AUTOSAR XML (schema 00047)
package /Composition/DiagUT/SwComponentTypes
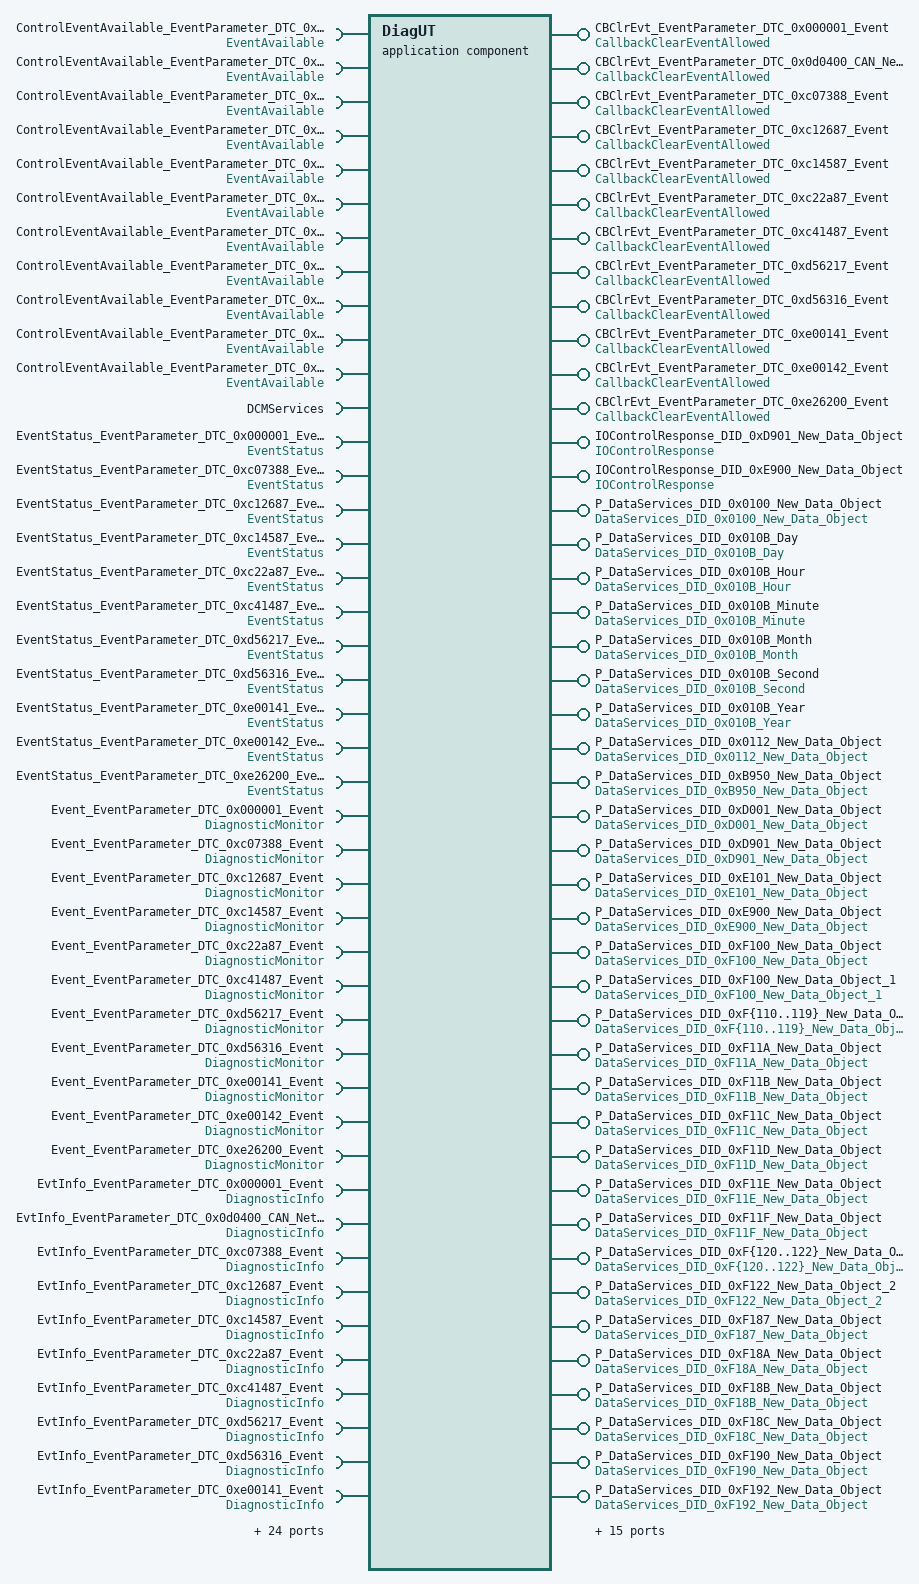
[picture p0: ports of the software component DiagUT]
  application sw component type DiagUT
    12 x provide port, all with provided-interface=CallbackClearEventAllowed:
      CBClrEvt_EventParameter_DTC_0x000001_Event
      CBClrEvt_EventParameter_DTC_0x0d0400_CAN_Network_ETAS_BusOff_Event
      CBClrEvt_EventParameter_DTC_0xc07388_Event
      CBClrEvt_EventParameter_DTC_0xc12687_Event
      CBClrEvt_EventParameter_DTC_0xc14587_Event
      CBClrEvt_EventParameter_DTC_0xc22a87_Event
      CBClrEvt_EventParameter_DTC_0xc41487_Event
      CBClrEvt_EventParameter_DTC_0xd56217_Event
      CBClrEvt_EventParameter_DTC_0xd56316_Event
      CBClrEvt_EventParameter_DTC_0xe00141_Event
      CBClrEvt_EventParameter_DTC_0xe00142_Event
      CBClrEvt_EventParameter_DTC_0xe26200_Event
    49 x require port:
      ControlEventAvailable_EventParameter_DTC_0x000001_Event: required-interface=EventAvailable
      ControlEventAvailable_EventParameter_DTC_0xc07388_Event: required-interface=EventAvailable
      ControlEventAvailable_EventParameter_DTC_0xc12687_Event: required-interface=EventAvailable
      ControlEventAvailable_EventParameter_DTC_0xc14587_Event: required-interface=EventAvailable
      ControlEventAvailable_EventParameter_DTC_0xc22a87_Event: required-interface=EventAvailable
      ControlEventAvailable_EventParameter_DTC_0xc41487_Event: required-interface=EventAvailable
      ControlEventAvailable_EventParameter_DTC_0xd56217_Event: required-interface=EventAvailable
      ControlEventAvailable_EventParameter_DTC_0xd56316_Event: required-interface=EventAvailable
      ControlEventAvailable_EventParameter_DTC_0xe00141_Event: required-interface=EventAvailable
      ControlEventAvailable_EventParameter_DTC_0xe00142_Event: required-interface=EventAvailable
      ControlEventAvailable_EventParameter_DTC_0xe26200_Event: required-interface=EventAvailable
      DCMServices: required-interface=DCMServices
      EventStatus_EventParameter_DTC_0x000001_Event: required-interface=EventStatus
      EventStatus_EventParameter_DTC_0xc07388_Event: required-interface=EventStatus
      EventStatus_EventParameter_DTC_0xc12687_Event: required-interface=EventStatus
      EventStatus_EventParameter_DTC_0xc14587_Event: required-interface=EventStatus
      EventStatus_EventParameter_DTC_0xc22a87_Event: required-interface=EventStatus
      EventStatus_EventParameter_DTC_0xc41487_Event: required-interface=EventStatus
      EventStatus_EventParameter_DTC_0xd56217_Event: required-interface=EventStatus
      EventStatus_EventParameter_DTC_0xd56316_Event: required-interface=EventStatus
      EventStatus_EventParameter_DTC_0xe00141_Event: required-interface=EventStatus
      EventStatus_EventParameter_DTC_0xe00142_Event: required-interface=EventStatus
      EventStatus_EventParameter_DTC_0xe26200_Event: required-interface=EventStatus
      Event_EventParameter_DTC_0x000001_Event: required-interface=DiagnosticMonitor
      Event_EventParameter_DTC_0xc07388_Event: required-interface=DiagnosticMonitor
      Event_EventParameter_DTC_0xc12687_Event: required-interface=DiagnosticMonitor
      Event_EventParameter_DTC_0xc14587_Event: required-interface=DiagnosticMonitor
      Event_EventParameter_DTC_0xc22a87_Event: required-interface=DiagnosticMonitor
      Event_EventParameter_DTC_0xc41487_Event: required-interface=DiagnosticMonitor
      Event_EventParameter_DTC_0xd56217_Event: required-interface=DiagnosticMonitor
      Event_EventParameter_DTC_0xd56316_Event: required-interface=DiagnosticMonitor
      Event_EventParameter_DTC_0xe00141_Event: required-interface=DiagnosticMonitor
      Event_EventParameter_DTC_0xe00142_Event: required-interface=DiagnosticMonitor
      Event_EventParameter_DTC_0xe26200_Event: required-interface=DiagnosticMonitor
      EvtInfo_EventParameter_DTC_0x000001_Event: required-interface=DiagnosticInfo
      EvtInfo_EventParameter_DTC_0x0d0400_CAN_Network_ETAS_BusOff_Event: required-interface=DiagnosticInfo
      EvtInfo_EventParameter_DTC_0xc07388_Event: required-interface=DiagnosticInfo
      EvtInfo_EventParameter_DTC_0xc12687_Event: required-interface=DiagnosticInfo
      EvtInfo_EventParameter_DTC_0xc14587_Event: required-interface=DiagnosticInfo
      EvtInfo_EventParameter_DTC_0xc22a87_Event: required-interface=DiagnosticInfo
      EvtInfo_EventParameter_DTC_0xc41487_Event: required-interface=DiagnosticInfo
      EvtInfo_EventParameter_DTC_0xd56217_Event: required-interface=DiagnosticInfo
      EvtInfo_EventParameter_DTC_0xd56316_Event: required-interface=DiagnosticInfo
      EvtInfo_EventParameter_DTC_0xe00141_Event: required-interface=DiagnosticInfo
      EvtInfo_EventParameter_DTC_0xe00142_Event: required-interface=DiagnosticInfo
      EvtInfo_EventParameter_DTC_0xe26200_Event: required-interface=DiagnosticInfo
      GeneralEvtInfo: required-interface=GeneralDiagnosticInfo
      IOControlRequest_DID_0xD901_New_Data_Object: required-interface=IOControlRequest_DID_0xD901_New_Data_Object
      IOControlRequest_DID_0xE900_New_Data_Object: required-interface=IOControlRequest_DID_0xE900_New_Data_Object
    provide port IOControlResponse_DID_0xD901_New_Data_Object: provided-interface=IOControlResponse
    provide port IOControlResponse_DID_0xE900_New_Data_Object: provided-interface=IOControlResponse
    require port OpCycle_DemOpCycle_DEM_POWER: required-interface=OperationCycle
    53 x provide port:
      P_DataServices_DID_0x0100_New_Data_Object: provided-interface=DataServices_DID_0x0100_New_Data_Object
      P_DataServices_DID_0x010B_Day: provided-interface=DataServices_DID_0x010B_Day
      P_DataServices_DID_0x010B_Hour: provided-interface=DataServices_DID_0x010B_Hour
      P_DataServices_DID_0x010B_Minute: provided-interface=DataServices_DID_0x010B_Minute
      P_DataServices_DID_0x010B_Month: provided-interface=DataServices_DID_0x010B_Month
      P_DataServices_DID_0x010B_Second: provided-interface=DataServices_DID_0x010B_Second
      P_DataServices_DID_0x010B_Year: provided-interface=DataServices_DID_0x010B_Year
      P_DataServices_DID_0x0112_New_Data_Object: provided-interface=DataServices_DID_0x0112_New_Data_Object
      P_DataServices_DID_0xB950_New_Data_Object: provided-interface=DataServices_DID_0xB950_New_Data_Object
      P_DataServices_DID_0xD001_New_Data_Object: provided-interface=DataServices_DID_0xD001_New_Data_Object
      P_DataServices_DID_0xD901_New_Data_Object: provided-interface=DataServices_DID_0xD901_New_Data_Object
      P_DataServices_DID_0xE101_New_Data_Object: provided-interface=DataServices_DID_0xE101_New_Data_Object
      P_DataServices_DID_0xE900_New_Data_Object: provided-interface=DataServices_DID_0xE900_New_Data_Object
      P_DataServices_DID_0xF100_New_Data_Object: provided-interface=DataServices_DID_0xF100_New_Data_Object
      P_DataServices_DID_0xF100_New_Data_Object_1: provided-interface=DataServices_DID_0xF100_New_Data_Object_1
      P_DataServices_DID_0xF{110..119}_New_Data_Object: provided-interface=DataServices_DID_0xF{110..119}_New_Data_Object
      P_DataServices_DID_0xF11A_New_Data_Object: provided-interface=DataServices_DID_0xF11A_New_Data_Object
      P_DataServices_DID_0xF11B_New_Data_Object: provided-interface=DataServices_DID_0xF11B_New_Data_Object
      P_DataServices_DID_0xF11C_New_Data_Object: provided-interface=DataServices_DID_0xF11C_New_Data_Object
      P_DataServices_DID_0xF11D_New_Data_Object: provided-interface=DataServices_DID_0xF11D_New_Data_Object
      P_DataServices_DID_0xF11E_New_Data_Object: provided-interface=DataServices_DID_0xF11E_New_Data_Object
      P_DataServices_DID_0xF11F_New_Data_Object: provided-interface=DataServices_DID_0xF11F_New_Data_Object
      P_DataServices_DID_0xF{120..122}_New_Data_Object: provided-interface=DataServices_DID_0xF{120..122}_New_Data_Object
      P_DataServices_DID_0xF122_New_Data_Object_2: provided-interface=DataServices_DID_0xF122_New_Data_Object_2
      P_DataServices_DID_0xF187_New_Data_Object: provided-interface=DataServices_DID_0xF187_New_Data_Object
      P_DataServices_DID_0xF18A_New_Data_Object: provided-interface=DataServices_DID_0xF18A_New_Data_Object
      P_DataServices_DID_0xF18B_New_Data_Object: provided-interface=DataServices_DID_0xF18B_New_Data_Object
      P_DataServices_DID_0xF18C_New_Data_Object: provided-interface=DataServices_DID_0xF18C_New_Data_Object
      P_DataServices_DID_0xF190_New_Data_Object: provided-interface=DataServices_DID_0xF190_New_Data_Object
      P_DataServices_DID_0xF192_New_Data_Object: provided-interface=DataServices_DID_0xF192_New_Data_Object
      P_DataServices_DID_0xF192_New_Data_Object_3: provided-interface=DataServices_DID_0xF192_New_Data_Object_3
      P_DataServices_DID_0xF194_New_Data_Object: provided-interface=DataServices_DID_0xF194_New_Data_Object
      P_DataServices_DID_0xF194_New_Data_Object_4: provided-interface=DataServices_DID_0xF194_New_Data_Object_4
      P_DataServices_DID_0xF198_New_Data_Object: provided-interface=DataServices_DID_0xF198_New_Data_Object
      P_DataServices_DID_0xF198_New_Data_Object_5: provided-interface=DataServices_DID_0xF198_New_Data_Object_5
      P_DataServices_DID_0xF1A{0..2}_New_Data_Object: provided-interface=DataServices_DID_0xF1A{0..2}_New_Data_Object
      P_DataServices_DID_0xF1A5_New_Data_Object: provided-interface=DataServices_DID_0xF1A5_New_Data_Object
      P_DataServices_DID_0xF1A8_New_Data_Object: provided-interface=DataServices_DID_0xF1A8_New_Data_Object
      P_DataServices_DID_0xF1A9_New_Data_Object: provided-interface=DataServices_DID_0xF1A9_New_Data_Object
      P_DataServices_DID_0xF1AA_New_Data_Object: provided-interface=DataServices_DID_0xF1AA_New_Data_Object
    17 x require port:
      RR_DcmCommunicationControl_ComMChannel_Can_Network_ETAS_Channel: required-interface=DcmCommunicationControl_Can_Network_ETAS_Channel_Can_Network_ETAS
      RR_DcmControlDTCSetting: required-interface=DcmControlDTCSetting
      RR_DcmDiagnosticSessionControl: required-interface=DcmDiagnosticSessionControl
      RR_DcmEcuReset: required-interface=DcmEcuReset
      R_DataServices_DID_0x0100_New_Data_Object: required-interface=DataServices_DID_0x0100_New_Data_Object
      R_DataServices_DID_0xF110_New_Data_Object: required-interface=DataServices_DID_0xF110_New_Data_Object
      R_DataServices_DID_0xF115_New_Data_Object: required-interface=DataServices_DID_0xF115_New_Data_Object
      R_DataServices_DID_0xF121_New_Data_Object: required-interface=DataServices_DID_0xF121_New_Data_Object
      R_DataServices_DID_0xF187_New_Data_Object: required-interface=DataServices_DID_0xF187_New_Data_Object
      R_DataServices_DID_0xF18B_New_Data_Object: required-interface=DataServices_DID_0xF18B_New_Data_Object
      R_DataServices_DID_0xF18C_New_Data_Object: required-interface=DataServices_DID_0xF18C_New_Data_Object
      R_DataServices_DID_0xF190_New_Data_Object: required-interface=DataServices_DID_0xF190_New_Data_Object
      R_DataServices_DID_0xF198_New_Data_Object: required-interface=DataServices_DID_0xF198_New_Data_Object
      R_DataServices_DID_0xF198_New_Data_Object_5: required-interface=DataServices_DID_0xF198_New_Data_Object_5
      R_DataServices_DID_0xF1A8_New_Data_Object: required-interface=DataServices_DID_0xF1A8_New_Data_Object
      R_DataServices_DID_0xF1A9_New_Data_Object: required-interface=DataServices_DID_0xF1A9_New_Data_Object
      R_DataServices_DID_0xF1AA_New_Data_Object: required-interface=DataServices_DID_0xF1AA_New_Data_Object
    5 x provide port:
      RoutineServices_DcmDspRoutine_Routine_Control_203: provided-interface=RoutineServices_Routine_Control_203
      RoutineServices_DcmDspRoutine_Routine_Control_ABFF: provided-interface=RoutineServices_Routine_Control_ABFF
      RoutineServices_DcmDspRoutine_X_Routine_Control_ABFE: provided-interface=RoutineServices_X_Routine_Control_ABFE
      SecurityAccess_UnlockedL1: provided-interface=SecurityAccess_UnlockedL1
      SecurityAccess_Unlocked_L3: provided-interface=SecurityAccess_Unlocked_L3
    require port StorageCond_DemStorageCondition_0: required-interface=StorageCondition
    behavior IB_DiagUT: data-type-mapping=[DTS_DcmDiagnosticSessionControl, DTS_DcmEcuReset, DTS_DcmControlDTCSetting, DTS_DcmDspDid_FOR_DEM_SR_FF_267_Year, DTS_DcmDspDid_FOR_DEM_SR_FF_267_Month, DTS_DcmDspDid_FOR_DEM_SR_FF_267_Day, DTS_DcmDspDid_FOR_DEM_SR_FF_267_Hour, DTS_DcmDspDid_FOR_DEM_SR_FF_267_Minute, DTS_DcmDspDid_FOR_DEM_SR_FF_267_Second, DTS_DcmDspDid_FOR_DEM_SR_FF_274_New_Data_Object, DTS_DcmDspDid_FOR_DEM_SR_FF_53249_New_Data_Object, DTS_DcmDspDid_FOR_DEM_SR_FF_55553_New_Data_Object, DTS_DcmDspDid_DID_0x0100_New_Data_Object, DTS_DcmDspDid_DID_0x010B_Year, DTS_DcmDspDid_DID_0x010B_Month, DTS_DcmDspDid_DID_0x010B_Day, DTS_DcmDspDid_DID_0x010B_Hour, DTS_DcmDspDid_DID_0x010B_Minute, DTS_DcmDspDid_DID_0x010B_Second, DTS_DcmDspDid_DID_0x0112_New_Data_Object, DTS_DcmDspDid_DID_0xB950_New_Data_Object, DTS_DcmDspDid_DID_0xD001_New_Data_Object, DTS_DcmDspDid_DID_0xD901_New_Data_Object, DTS_DcmDspDid_DID_0xE101_New_Data_Object, DTS_DcmDspDid_DID_0xE900_New_Data_Object, DTS_DcmDspDid_DID_0xF100_New_Data_Object, DTS_DcmDspDid_DID_0xF100_New_Data_Object_1, DTS_DcmDspDid_DID_0xF110_New_Data_Object, DTS_DcmDspDid_DID_0xF111_New_Data_Object, DTS_DcmDspDid_DID_0xF112_New_Data_Object, DTS_DcmDspDid_DID_0xF113_New_Data_Object, DTS_DcmDspDid_DID_0xF114_New_Data_Object, DTS_DcmDspDid_DID_0xF115_New_Data_Object, DTS_DcmDspDid_DID_0xF116_New_Data_Object, DTS_DcmDspDid_DID_0xF117_New_Data_Object, DTS_DcmDspDid_DID_0xF118_New_Data_Object, DTS_DcmDspDid_DID_0xF119_New_Data_Object, DTS_DcmDspDid_DID_0xF11A_New_Data_Object, DTS_DcmDspDid_DID_0xF11B_New_Data_Object, DTS_DcmDspDid_DID_0xF11C_New_Data_Object, DTS_DcmDspDid_DID_0xF11D_New_Data_Object, DTS_DcmDspDid_DID_0xF11E_New_Data_Object, DTS_DcmDspDid_DID_0xF11F_New_Data_Object, DTS_DcmDspDid_DID_0xF120_New_Data_Object, DTS_DcmDspDid_DID_0xF121_New_Data_Object, DTS_DcmDspDid_DID_0xF122_New_Data_Object, DTS_DcmDspDid_DID_0xF122_New_Data_Object_2, DTS_DcmDspDid_DID_0xF187_New_Data_Object, DTS_DcmDspDid_DID_0xF18A_New_Data_Object, DTS_DcmDspDid_DID_0xF18B_New_Data_Object, DTS_DcmDspDid_DID_0xF18C_New_Data_Object, DTS_DcmDspDid_DID_0xF190_New_Data_Object, DTS_DcmDspDid_DID_0xF192_New_Data_Object, DTS_DcmDspDid_DID_0xF192_New_Data_Object_3, DTS_DcmDspDid_DID_0xF194_New_Data_Object, DTS_DcmDspDid_DID_0xF194_New_Data_Object_4, DTS_DcmDspDid_DID_0xF198_New_Data_Object, DTS_DcmDspDid_DID_0xF198_New_Data_Object_5, DTS_DcmDspDid_DID_0xF1A0_New_Data_Object, DTS_DcmDspDid_DID_0xF1A1_New_Data_Object, DTS_DcmDspDid_DID_0xF1A2_New_Data_Object, DTS_DcmDspDid_DID_0xF1A5_New_Data_Object, DTS_DcmDspDid_DID_0xF1A8_New_Data_Object, DTS_DcmDspDid_DID_0xF1A9_New_Data_Object, DTS_DcmDspDid_DID_0xF1AA_New_Data_Object, DTS_DcmCommunicationControl_Can_Network_ETAS_Channel_Can_Network_ETAS, DTS_DcmDspRoutine_Routine_Control_203_StartOut_DcmDspStartRoutineOutSignal_0, DTS_DcmDspRoutine_Routine_Control_ABFF_RequestResultsOut_DcmDspRequestRoutineResultsOutSignal_0]
      16 x operation invoked event:
        OIE_CBClrEvt_EventParameter_DTC_0x0d0400_CAN_Network_ETAS_BusOff_Event_ClearEventAllowed_Ev: start-on-event=CBClrEvt_EventParameter_DTC_0x0d0400_CAN_Network_ETAS_BusOff_Event_ClearEventAllowed, operation=CBClrEvt_EventParameter_DTC_0x0d0400_CAN_Network_ETAS_BusOff_Event.ClearEventAllowed
        OIE_CBClrEvt_EventParameter_DTC_0xc07388_Event_ClearEventAllowed_Ev: start-on-event=CBClrEvt_EventParameter_DTC_0xc07388_Event_ClearEventAllowed, operation=CBClrEvt_EventParameter_DTC_0xc07388_Event.ClearEventAllowed
        OIE_CBClrEvt_EventParameter_DTC_0xc12687_Event_ClearEventAllowed_Ev: start-on-event=CBClrEvt_EventParameter_DTC_0xc12687_Event_ClearEventAllowed, operation=CBClrEvt_EventParameter_DTC_0xc12687_Event.ClearEventAllowed
        OIE_CBClrEvt_EventParameter_DTC_0xc14587_Event_ClearEventAllowed_Ev: start-on-event=CBClrEvt_EventParameter_DTC_0xc14587_Event_ClearEventAllowed, operation=CBClrEvt_EventParameter_DTC_0xc14587_Event.ClearEventAllowed
        OIE_CBClrEvt_EventParameter_DTC_0xc22a87_Event_ClearEventAllowed_Ev: start-on-event=CBClrEvt_EventParameter_DTC_0xc22a87_Event_ClearEventAllowed, operation=CBClrEvt_EventParameter_DTC_0xc22a87_Event.ClearEventAllowed
        OIE_CBClrEvt_EventParameter_DTC_0xc41487_Event_ClearEventAllowed_Ev: start-on-event=CBClrEvt_EventParameter_DTC_0xc41487_Event_ClearEventAllowed, operation=CBClrEvt_EventParameter_DTC_0xc41487_Event.ClearEventAllowed
        OIE_CBClrEvt_EventParameter_DTC_0xd56217_Event_ClearEventAllowed_Ev: start-on-event=CBClrEvt_EventParameter_DTC_0xd56217_Event_ClearEventAllowed, operation=CBClrEvt_EventParameter_DTC_0xd56217_Event.ClearEventAllowed
        OIE_CBClrEvt_EventParameter_DTC_0xd56316_Event_ClearEventAllowed_Ev: start-on-event=CBClrEvt_EventParameter_DTC_0xd56316_Event_ClearEventAllowed, operation=CBClrEvt_EventParameter_DTC_0xd56316_Event.ClearEventAllowed
        OIE_CBClrEvt_EventParameter_DTC_0xe00141_Event_ClearEventAllowed_Ev: start-on-event=CBClrEvt_EventParameter_DTC_0xe00141_Event_ClearEventAllowed, operation=CBClrEvt_EventParameter_DTC_0xe00141_Event.ClearEventAllowed
        OIE_CBClrEvt_EventParameter_DTC_0xe00142_Event_ClearEventAllowed_Ev: start-on-event=CBClrEvt_EventParameter_DTC_0xe00142_Event_ClearEventAllowed, operation=CBClrEvt_EventParameter_DTC_0xe00142_Event.ClearEventAllowed
        OIE_CBClrEvt_EventParameter_DTC_0xe26200_Event_ClearEventAllowed_Ev: start-on-event=CBClrEvt_EventParameter_DTC_0xe26200_Event_ClearEventAllowed, operation=CBClrEvt_EventParameter_DTC_0xe26200_Event.ClearEventAllowed
        OIE_ClearEventAllowed_Ev: start-on-event=ClearEventAllowed, operation=CBClrEvt_EventParameter_DTC_0x000001_Event.ClearEventAllowed
        OIE_SecurityAccess_Unlocked_L1_CompareKey_Ev: start-on-event=SecurityAccess_Unlocked_L1_CompareKey, operation=SecurityAccess_UnlockedL1.CompareKey
        OIE_SecurityAccess_Unlocked_L1_GetSeed_Ev: start-on-event=SecurityAccess_Unlocked_L1_GetSeed, operation=SecurityAccess_UnlockedL1.GetSeed
        OIE_SecurityAccess_Unlocked_L3_CompareKey_Ev: start-on-event=SecurityAccess_Unlocked_L3_CompareKey, operation=SecurityAccess_Unlocked_L3.CompareKey
        OIE_SecurityAccess_Unlocked_L3_GetSeed_Ev: start-on-event=SecurityAccess_Unlocked_L3_GetSeed, operation=SecurityAccess_Unlocked_L3.GetSeed
      41 x timing event, all with period=0.01:
        TE_ClearPrestoredFreezeFrame_Adapt_Appl: start-on-event=ClearPrestoredFreezeFrame_Adapt_Appl
        TE_Dcm_GetActiveProtocol_Adapt_Appl: start-on-event=Dcm_GetActiveProtocol_Adapt_Appl
        TE_Dcm_GetSecurityLevel_Adapt_Appl: start-on-event=Dcm_GetSecurityLevel_Adapt_Appl
        TE_Dcm_GetSesCtrlType_Adapt_Appl: start-on-event=Dcm_GetSesCtrlType_Adapt_Appl
        TE_Dcm_ResetToDefaultSession_Adapt_Appl: start-on-event=Dcm_ResetToDefaultSession_Adapt_Appl
        TE_Dcm_SetActiveDiagnostic_Adapt_Appl: start-on-event=Dcm_SetActiveDiagnostic_Adapt_Appl
        TE_Dem_GetDTCOfEvent_GeneralEvtInfo_Adapt_Appl: start-on-event=Dem_GetDTCOfEvent_GeneralEvtInfo_Adapt_Appl
        TE_Dem_GetEventExtendedDataRecordEx_GeneralEvtInfo_Adapt_Appl: start-on-event=Dem_GetEventExtendedDataRecordEx_GeneralEvtInfo_Adapt_Appl
        TE_Dem_GetEventExtendedDataRecord_GeneralEvtInfo_Adapt_Appl: start-on-event=Dem_GetEventExtendedDataRecord_GeneralEvtInfo_Adapt_Appl
        TE_Dem_GetEventFailed_GeneralEvtInfo_Adapt_Appl: start-on-event=Dem_GetEventFailed_GeneralEvtInfo_Adapt_Appl
        TE_Dem_GetEventFreezeFrameDataEx_GeneralEvtInfo_Adapt_Appl: start-on-event=Dem_GetEventFreezeFrameDataEx_GeneralEvtInfo_Adapt_Appl
        TE_Dem_GetEventFreezeFrameData_GeneralEvtInfo_Adapt_Appl: start-on-event=Dem_GetEventFreezeFrameData_GeneralEvtInfo_Adapt_Appl
        TE_Dem_GetEventIdCausingLastDetError_Adapt_Appl: start-on-event=Dem_GetEventIdCausingLastDetError_Adapt_Appl
        TE_Dem_GetEventStatus_GeneralEvtInfo_Adapt_Appl: start-on-event=Dem_GetEventStatus_GeneralEvtInfo_Adapt_Appl
        TE_Dem_GetEventTested_GeneralEvtInfo_Adapt_Appl: start-on-event=Dem_GetEventTested_GeneralEvtInfo_Adapt_Appl
        TE_Dem_GetFaultDetectionCounter_GeneralEvtInfo_Adapt_Appl: start-on-event=Dem_GetFaultDetectionCounter_GeneralEvtInfo_Adapt_Appl
        TE_GetCycleQualified_Adapt_Appl: start-on-event=GetCycleQualified_Adapt_Appl
        TE_GetDTCOfEvent_Adapt_Appl: start-on-event=GetDTCOfEvent_Adapt_Appl
        TE_GetDebouncingOfEvent_Adapt_Appl: start-on-event=GetDebouncingOfEvent_Adapt_Appl
        TE_GetDebouncingOfEvent_GeneralEvtInfo_Adapt_Appl: start-on-event=GetDebouncingOfEvent_GeneralEvtInfo_Adapt_Appl
        TE_GetEventExtendedDataRecordEx_Adapt_Appl: start-on-event=GetEventExtendedDataRecordEx_Adapt_Appl
        TE_GetEventExtendedDataRecord_Adapt_Appl: start-on-event=GetEventExtendedDataRecord_Adapt_Appl
        TE_GetEventFailed_Adapt_Appl: start-on-event=GetEventFailed_Adapt_Appl
        TE_GetEventFreezeFrameDataEx_Adapt_Appl: start-on-event=GetEventFreezeFrameDataEx_Adapt_Appl
        TE_GetEventFreezeFrameData_Adapt_Appl: start-on-event=GetEventFreezeFrameData_Adapt_Appl
        TE_GetEventStatus_Adapt_Appl: start-on-event=GetEventStatus_Adapt_Appl
        TE_GetEventTested_Adapt_Appl: start-on-event=GetEventTested_Adapt_Appl
        TE_GetFaultDetectionCounter_Adapt_Appl: start-on-event=GetFaultDetectionCounter_Adapt_Appl
        TE_GetOperationCycleState_Adapt_Appl: start-on-event=GetOperationCycleState_Adapt_Appl
        TE_GetStorageCondition_Adapt_Appl: start-on-event=GetStorageCondition_Adapt_Appl
        TE_PrestoreFreezeFrame_Adapt_Appl: start-on-event=PrestoreFreezeFrame_Adapt_Appl
        TE_ResetEventDebounceStatus_Adapt_Appl: start-on-event=ResetEventDebounceStatus_Adapt_Appl
        TE_ResetEventStatus_Adapt_Appl: start-on-event=ResetEventStatus_Adapt_Appl
        TE_SetCycleQualified_Adapt_Appl: start-on-event=SetCycleQualified_Adapt_Appl
        TE_SetEventAvailable_Adapt_Appl: start-on-event=SetEventAvailable_Adapt_Appl
        TE_SetEventStatusWithEnvdata_Adapt_Appl: start-on-event=SetEventStatusWithEnvdata_Adapt_Appl
        TE_SetEventStatus_Adapt_Appl: start-on-event=SetEventStatus_Adapt_Appl
        TE_SetOperationCycleState_Adapt_Appl: start-on-event=SetOperationCycleState_Adapt_Appl
        TE_SetStorageCondition_Adapt_Appl: start-on-event=SetStorageCondition_Adapt_Appl
        TE_SetWIRStatus_Adapt_Appl: start-on-event=SetWIRStatus_Adapt_Appl
        TE_Dcm_MainFunction_Adapt_Appl: start-on-event=Dcm_MainFunction_Adapt_Appl
      4 x operation invoked event:
        OIE_RoutineServices_DcmDspRoutine_Routine_Control_203_Start_Ev: start-on-event=RoutineServices_DcmDspRoutine_Routine_Control_203_Start, operation=RoutineServices_DcmDspRoutine_Routine_Control_203.Start
        OIE_RoutineServices_DcmDspRoutine_Routine_Control_ABFF_Start_Ev: start-on-event=RoutineServices_DcmDspRoutine_Routine_Control_ABFF_Start, operation=RoutineServices_DcmDspRoutine_Routine_Control_ABFF.Start
        OIE_RoutineServices_DcmDspRoutine_Routine_Control_ABFF_RequestResults_Ev: start-on-event=RoutineServices_DcmDspRoutine_Routine_Control_ABFF_RequestResults, operation=RoutineServices_DcmDspRoutine_Routine_Control_ABFF.RequestResults
        OIE_RoutineServices_DcmDspRoutine_X_Routine_Control_ABFE_Start_Ev: start-on-event=RoutineServices_DcmDspRoutine_X_Routine_Control_ABFE_Start, operation=RoutineServices_DcmDspRoutine_X_Routine_Control_ABFE.Start
      61 x runnable:
        CBClrEvt_EventParameter_DTC_0x0d0400_CAN_Network_ETAS_BusOff_Event_ClearEventAllowed: can-be-invoked-concurrently=true
        CBClrEvt_EventParameter_DTC_0xc07388_Event_ClearEventAllowed: can-be-invoked-concurrently=true
        CBClrEvt_EventParameter_DTC_0xc12687_Event_ClearEventAllowed: can-be-invoked-concurrently=true
        CBClrEvt_EventParameter_DTC_0xc14587_Event_ClearEventAllowed: can-be-invoked-concurrently=true
        CBClrEvt_EventParameter_DTC_0xc22a87_Event_ClearEventAllowed: can-be-invoked-concurrently=true
        CBClrEvt_EventParameter_DTC_0xc41487_Event_ClearEventAllowed: can-be-invoked-concurrently=true
        CBClrEvt_EventParameter_DTC_0xd56217_Event_ClearEventAllowed: can-be-invoked-concurrently=true
        CBClrEvt_EventParameter_DTC_0xd56316_Event_ClearEventAllowed: can-be-invoked-concurrently=true
        CBClrEvt_EventParameter_DTC_0xe00141_Event_ClearEventAllowed: can-be-invoked-concurrently=true
        CBClrEvt_EventParameter_DTC_0xe00142_Event_ClearEventAllowed: can-be-invoked-concurrently=true
        CBClrEvt_EventParameter_DTC_0xe26200_Event_ClearEventAllowed: can-be-invoked-concurrently=true
        ClearEventAllowed: can-be-invoked-concurrently=true
        ClearPrestoredFreezeFrame_Adapt_Appl
          11 x sync call:
            SynchronousServerCallPoint_0: operation=Event_EventParameter_DTC_0x000001_Event.ClearPrestoredFreezeFrame
            SynchronousServerCallPoint_1: operation=Event_EventParameter_DTC_0xc07388_Event.ClearPrestoredFreezeFrame
            SynchronousServerCallPoint_10: operation=Event_EventParameter_DTC_0xe26200_Event.ClearPrestoredFreezeFrame
            SynchronousServerCallPoint_2: operation=Event_EventParameter_DTC_0xc12687_Event.ClearPrestoredFreezeFrame
            SynchronousServerCallPoint_3: operation=Event_EventParameter_DTC_0xc14587_Event.ClearPrestoredFreezeFrame
            SynchronousServerCallPoint_4: operation=Event_EventParameter_DTC_0xc22a87_Event.ClearPrestoredFreezeFrame
            SynchronousServerCallPoint_5: operation=Event_EventParameter_DTC_0xc41487_Event.ClearPrestoredFreezeFrame
            SynchronousServerCallPoint_6: operation=Event_EventParameter_DTC_0xd56217_Event.ClearPrestoredFreezeFrame
            SynchronousServerCallPoint_7: operation=Event_EventParameter_DTC_0xd56316_Event.ClearPrestoredFreezeFrame
            SynchronousServerCallPoint_8: operation=Event_EventParameter_DTC_0xe00141_Event.ClearPrestoredFreezeFrame
            SynchronousServerCallPoint_9: operation=Event_EventParameter_DTC_0xe00142_Event.ClearPrestoredFreezeFrame
        Dcm_GetActiveProtocol_Adapt_Appl
          sync call SynchronousServerCallPoint_0: operation=DCMServices.GetActiveProtocol
        Dcm_GetSecurityLevel_Adapt_Appl
          sync call SynchronousServerCallPoint_0: operation=DCMServices.GetSecurityLevel
        Dcm_GetSesCtrlType_Adapt_Appl
          sync call SynchronousServerCallPoint_0: operation=DCMServices.GetSesCtrlType
        Dcm_MainFunction_Adapt_Appl
          data-receive-point-by-arguments:
            15 x access:
              DRPA_IOControlRequest_DID_0xD901_New_Data_Object_IOControlRequest_DID_0xD901_New_Data_Object: accessed-variable=IOControlRequest_DID_0xD901_New_Data_Object.IOControlRequest_DID_0xD901_New_Data_Object
              DRPA_IOControlRequest_DID_0xE900_New_Data_Object_IOControlRequest_DID_0xE900_New_Data_Object: accessed-variable=IOControlRequest_DID_0xE900_New_Data_Object.IOControlRequest_DID_0xE900_New_Data_Object
              DRPA_R_DataServices_DID_0x0100_New_Data_Object_Data: accessed-variable=R_DataServices_DID_0x0100_New_Data_Object.Data
              DRPA_R_DataServices_DID_0xF110_New_Data_Object_Data: accessed-variable=R_DataServices_DID_0xF110_New_Data_Object.Data
              DRPA_R_DataServices_DID_0xF115_New_Data_Object_Data: accessed-variable=R_DataServices_DID_0xF115_New_Data_Object.Data
              DRPA_R_DataServices_DID_0xF121_New_Data_Object_Data: accessed-variable=R_DataServices_DID_0xF121_New_Data_Object.Data
              DRPA_R_DataServices_DID_0xF187_New_Data_Object_Data: accessed-variable=R_DataServices_DID_0xF187_New_Data_Object.Data
              DRPA_R_DataServices_DID_0xF18B_New_Data_Object_Data: accessed-variable=R_DataServices_DID_0xF18B_New_Data_Object.Data
              DRPA_R_DataServices_DID_0xF18C_New_Data_Object_Data: accessed-variable=R_DataServices_DID_0xF18C_New_Data_Object.Data
              DRPA_R_DataServices_DID_0xF190_New_Data_Object_Data: accessed-variable=R_DataServices_DID_0xF190_New_Data_Object.Data
              DRPA_R_DataServices_DID_0xF198_New_Data_Object_5_Data: accessed-variable=R_DataServices_DID_0xF198_New_Data_Object_5.Data
              DRPA_R_DataServices_DID_0xF198_New_Data_Object_Data: accessed-variable=R_DataServices_DID_0xF198_New_Data_Object.Data
              DRPA_R_DataServices_DID_0xF1A8_New_Data_Object_Data: accessed-variable=R_DataServices_DID_0xF1A8_New_Data_Object.Data
              DRPA_R_DataServices_DID_0xF1A9_New_Data_Object_Data: accessed-variable=R_DataServices_DID_0xF1A9_New_Data_Object.Data
              DRPA_R_DataServices_DID_0xF1AA_New_Data_Object_Data: accessed-variable=R_DataServices_DID_0xF1AA_New_Data_Object.Data
          data-send-points:
            55 x access:
              DSP_IOControlResponse_DID_0xD901_New_Data_Object_IOOperationResponse: accessed-variable=IOControlResponse_DID_0xD901_New_Data_Object.IOOperationResponse
              DSP_IOControlResponse_DID_0xE900_New_Data_Object_IOOperationResponse: accessed-variable=IOControlResponse_DID_0xE900_New_Data_Object.IOOperationResponse
              DSP_P_DataServices_DID_0x0100_New_Data_Object_Data: accessed-variable=P_DataServices_DID_0x0100_New_Data_Object.Data
              DSP_P_DataServices_DID_0x010B_Day_Data: accessed-variable=P_DataServices_DID_0x010B_Day.Data
              DSP_P_DataServices_DID_0x010B_Hour_Data: accessed-variable=P_DataServices_DID_0x010B_Hour.Data
              DSP_P_DataServices_DID_0x010B_Minute_Data: accessed-variable=P_DataServices_DID_0x010B_Minute.Data
              DSP_P_DataServices_DID_0x010B_Month_Data: accessed-variable=P_DataServices_DID_0x010B_Month.Data
              DSP_P_DataServices_DID_0x010B_Second_Data: accessed-variable=P_DataServices_DID_0x010B_Second.Data
              DSP_P_DataServices_DID_0x010B_Year_Data: accessed-variable=P_DataServices_DID_0x010B_Year.Data
              DSP_P_DataServices_DID_0x0112_New_Data_Object_Data: accessed-variable=P_DataServices_DID_0x0112_New_Data_Object.Data
              DSP_P_DataServices_DID_0xB950_New_Data_Object_Data: accessed-variable=P_DataServices_DID_0xB950_New_Data_Object.Data
              DSP_P_DataServices_DID_0xD001_New_Data_Object_Data: accessed-variable=P_DataServices_DID_0xD001_New_Data_Object.Data
              DSP_P_DataServices_DID_0xD901_New_Data_Object_Data: accessed-variable=P_DataServices_DID_0xD901_New_Data_Object.Data
              DSP_P_DataServices_DID_0xE101_New_Data_Object_Data: accessed-variable=P_DataServices_DID_0xE101_New_Data_Object.Data
              DSP_P_DataServices_DID_0xE900_New_Data_Object_Data: accessed-variable=P_DataServices_DID_0xE900_New_Data_Object.Data
              DSP_P_DataServices_DID_0xF100_New_Data_Object_1_Data: accessed-variable=P_DataServices_DID_0xF100_New_Data_Object_1.Data
              DSP_P_DataServices_DID_0xF100_New_Data_Object_Data: accessed-variable=P_DataServices_DID_0xF100_New_Data_Object.Data
              DSP_P_DataServices_DID_0xF{110..119}_New_Data_Object_Data: accessed-variable=P_DataServices_DID_0xF{110..119}_New_Data_Object.Data
              DSP_P_DataServices_DID_0xF11A_New_Data_Object_Data: accessed-variable=P_DataServices_DID_0xF11A_New_Data_Object.Data
              DSP_P_DataServices_DID_0xF11B_New_Data_Object_Data: accessed-variable=P_DataServices_DID_0xF11B_New_Data_Object.Data
              DSP_P_DataServices_DID_0xF11C_New_Data_Object_Data: accessed-variable=P_DataServices_DID_0xF11C_New_Data_Object.Data
              DSP_P_DataServices_DID_0xF11D_New_Data_Object_Data: accessed-variable=P_DataServices_DID_0xF11D_New_Data_Object.Data
              DSP_P_DataServices_DID_0xF11E_New_Data_Object_Data: accessed-variable=P_DataServices_DID_0xF11E_New_Data_Object.Data
              DSP_P_DataServices_DID_0xF11F_New_Data_Object_Data: accessed-variable=P_DataServices_DID_0xF11F_New_Data_Object.Data
              DSP_P_DataServices_DID_0xF120_New_Data_Object_Data: accessed-variable=P_DataServices_DID_0xF120_New_Data_Object.Data
              DSP_P_DataServices_DID_0xF121_New_Data_Object_Data: accessed-variable=P_DataServices_DID_0xF121_New_Data_Object.Data
              DSP_P_DataServices_DID_0xF122_New_Data_Object_2_Data: accessed-variable=P_DataServices_DID_0xF122_New_Data_Object_2.Data
              DSP_P_DataServices_DID_0xF122_New_Data_Object_Data: accessed-variable=P_DataServices_DID_0xF122_New_Data_Object.Data
              DSP_P_DataServices_DID_0xF187_New_Data_Object_Data: accessed-variable=P_DataServices_DID_0xF187_New_Data_Object.Data
              DSP_P_DataServices_DID_0xF18A_New_Data_Object_Data: accessed-variable=P_DataServices_DID_0xF18A_New_Data_Object.Data
              DSP_P_DataServices_DID_0xF18B_New_Data_Object_Data: accessed-variable=P_DataServices_DID_0xF18B_New_Data_Object.Data
              DSP_P_DataServices_DID_0xF18C_New_Data_Object_Data: accessed-variable=P_DataServices_DID_0xF18C_New_Data_Object.Data
              DSP_P_DataServices_DID_0xF190_New_Data_Object_Data: accessed-variable=P_DataServices_DID_0xF190_New_Data_Object.Data
              DSP_P_DataServices_DID_0xF192_New_Data_Object_3_Data: accessed-variable=P_DataServices_DID_0xF192_New_Data_Object_3.Data
              DSP_P_DataServices_DID_0xF192_New_Data_Object_Data: accessed-variable=P_DataServices_DID_0xF192_New_Data_Object.Data
              DSP_P_DataServices_DID_0xF194_New_Data_Object_4_Data: accessed-variable=P_DataServices_DID_0xF194_New_Data_Object_4.Data
              DSP_P_DataServices_DID_0xF194_New_Data_Object_Data: accessed-variable=P_DataServices_DID_0xF194_New_Data_Object.Data
              DSP_P_DataServices_DID_0xF198_New_Data_Object_5_Data: accessed-variable=P_DataServices_DID_0xF198_New_Data_Object_5.Data
              DSP_P_DataServices_DID_0xF198_New_Data_Object_Data: accessed-variable=P_DataServices_DID_0xF198_New_Data_Object.Data
              DSP_P_DataServices_DID_0xF1A{0..2}_New_Data_Object_Data: accessed-variable=P_DataServices_DID_0xF1A{0..2}_New_Data_Object.Data
              DSP_P_DataServices_DID_0xF1A5_New_Data_Object_Data: accessed-variable=P_DataServices_DID_0xF1A5_New_Data_Object.Data
              DSP_P_DataServices_DID_0xF1A8_New_Data_Object_Data: accessed-variable=P_DataServices_DID_0xF1A8_New_Data_Object.Data
              DSP_P_DataServices_DID_0xF1A9_New_Data_Object_Data: accessed-variable=P_DataServices_DID_0xF1A9_New_Data_Object.Data
              DSP_P_DataServices_DID_0xF1AA_New_Data_Object_Data: accessed-variable=P_DataServices_DID_0xF1AA_New_Data_Object.Data
          mode-access-points:
            RR_DcmDiagnosticSessionControl.MDGP_DcmDiagnosticSessionControl
            RR_DcmEcuReset.MDGP_DcmEcuReset
            RR_DcmControlDTCSetting.MDGP_DcmControlDTCSetting
            RR_DcmCommunicationControl_ComMChannel_Can_Network_ETAS_Channel.MDGP_DcmCommunicationControl_Can_Network_ETAS_Channel_Can_Network_ETAS
        Dcm_ResetToDefaultSession_Adapt_Appl
          sync call SynchronousServerCallPoint_0: operation=DCMServices.ResetToDefaultSession
        Dcm_SetActiveDiagnostic_Adapt_Appl
          sync call SynchronousServerCallPoint_0: operation=DCMServices.SetActiveDiagnostic
        Dem_GetDTCOfEvent_GeneralEvtInfo_Adapt_Appl
          sync call SynchronousServerCallPoint_0: operation=GeneralEvtInfo.GetDTCOfEvent
        Dem_GetEventExtendedDataRecordEx_GeneralEvtInfo_Adapt_Appl
          sync call SynchronousServerCallPoint_0: operation=GeneralEvtInfo.GetEventExtendedDataRecordEx
        Dem_GetEventExtendedDataRecord_GeneralEvtInfo_Adapt_Appl
          sync call SynchronousServerCallPoint_0: operation=GeneralEvtInfo.GetEventExtendedDataRecord
        Dem_GetEventFailed_GeneralEvtInfo_Adapt_Appl
          sync call SynchronousServerCallPoint_0: operation=GeneralEvtInfo.GetEventFailed
        Dem_GetEventFreezeFrameDataEx_GeneralEvtInfo_Adapt_Appl
          sync call SynchronousServerCallPoint_0: operation=GeneralEvtInfo.GetEventFreezeFrameDataEx
        Dem_GetEventFreezeFrameData_GeneralEvtInfo_Adapt_Appl
          sync call SynchronousServerCallPoint_0: operation=GeneralEvtInfo.GetEventFreezeFrameData
        Dem_GetEventIdCausingLastDetError_Adapt_Appl
          sync call SynchronousServerCallPoint_0: operation=GeneralEvtInfo.GetEventIdCausingLastDetError
        Dem_GetEventStatus_GeneralEvtInfo_Adapt_Appl
          sync call SynchronousServerCallPoint_0: operation=GeneralEvtInfo.GetEventStatus
        Dem_GetEventTested_GeneralEvtInfo_Adapt_Appl
          sync call SynchronousServerCallPoint_0: operation=GeneralEvtInfo.GetEventTested
        Dem_GetFaultDetectionCounter_GeneralEvtInfo_Adapt_Appl
          sync call SynchronousServerCallPoint_0: operation=GeneralEvtInfo.GetFaultDetectionCounter
        GetCycleQualified_Adapt_Appl
          sync call SynchronousServerCallPoint_0: operation=OpCycle_DemOpCycle_DEM_POWER.GetCycleQualified
        GetDTCOfEvent_Adapt_Appl
          12 x sync call:
            SynchronousServerCallPoint_26: operation=EvtInfo_EventParameter_DTC_0x000001_Event.GetDTCOfEvent
            SynchronousServerCallPoint_27: operation=EvtInfo_EventParameter_DTC_0x0d0400_CAN_Network_ETAS_BusOff_Event.GetDTCOfEvent
            SynchronousServerCallPoint_28: operation=EvtInfo_EventParameter_DTC_0xc07388_Event.GetDTCOfEvent
            SynchronousServerCallPoint_29: operation=EvtInfo_EventParameter_DTC_0xc12687_Event.GetDTCOfEvent
            SynchronousServerCallPoint_30: operation=EvtInfo_EventParameter_DTC_0xc14587_Event.GetDTCOfEvent
            SynchronousServerCallPoint_31: operation=EvtInfo_EventParameter_DTC_0xc22a87_Event.GetDTCOfEvent
            SynchronousServerCallPoint_32: operation=EvtInfo_EventParameter_DTC_0xc41487_Event.GetDTCOfEvent
            SynchronousServerCallPoint_33: operation=EvtInfo_EventParameter_DTC_0xd56217_Event.GetDTCOfEvent
            SynchronousServerCallPoint_34: operation=EvtInfo_EventParameter_DTC_0xd56316_Event.GetDTCOfEvent
            SynchronousServerCallPoint_35: operation=EvtInfo_EventParameter_DTC_0xe00141_Event.GetDTCOfEvent
            SynchronousServerCallPoint_36: operation=EvtInfo_EventParameter_DTC_0xe00142_Event.GetDTCOfEvent
            SynchronousServerCallPoint_37: operation=EvtInfo_EventParameter_DTC_0xe26200_Event.GetDTCOfEvent
        GetDebouncingOfEvent_Adapt_Appl
          12 x sync call:
            SynchronousServerCallPoint_26: operation=EvtInfo_EventParameter_DTC_0x000001_Event.GetDebouncingOfEvent
            SynchronousServerCallPoint_27: operation=EvtInfo_EventParameter_DTC_0x0d0400_CAN_Network_ETAS_BusOff_Event.GetDebouncingOfEvent
            SynchronousServerCallPoint_28: operation=EvtInfo_EventParameter_DTC_0xc07388_Event.GetDebouncingOfEvent
            SynchronousServerCallPoint_29: operation=EvtInfo_EventParameter_DTC_0xc12687_Event.GetDebouncingOfEvent
            SynchronousServerCallPoint_30: operation=EvtInfo_EventParameter_DTC_0xc14587_Event.GetDebouncingOfEvent
            SynchronousServerCallPoint_31: operation=EvtInfo_EventParameter_DTC_0xc22a87_Event.GetDebouncingOfEvent
            SynchronousServerCallPoint_32: operation=EvtInfo_EventParameter_DTC_0xc41487_Event.GetDebouncingOfEvent
            SynchronousServerCallPoint_33: operation=EvtInfo_EventParameter_DTC_0xd56217_Event.GetDebouncingOfEvent
            SynchronousServerCallPoint_34: operation=EvtInfo_EventParameter_DTC_0xd56316_Event.GetDebouncingOfEvent
            SynchronousServerCallPoint_35: operation=EvtInfo_EventParameter_DTC_0xe00141_Event.GetDebouncingOfEvent
            SynchronousServerCallPoint_36: operation=EvtInfo_EventParameter_DTC_0xe00142_Event.GetDebouncingOfEvent
            SynchronousServerCallPoint_37: operation=EvtInfo_EventParameter_DTC_0xe26200_Event.GetDebouncingOfEvent
        GetDebouncingOfEvent_GeneralEvtInfo_Adapt_Appl
          sync call SynchronousServerCallPoint_0: operation=GeneralEvtInfo.GetDebouncingOfEvent
        GetEventExtendedDataRecordEx_Adapt_Appl
          12 x sync call:
            SynchronousServerCallPoint_26: operation=EvtInfo_EventParameter_DTC_0x000001_Event.GetEventExtendedDataRecordEx
            SynchronousServerCallPoint_27: operation=EvtInfo_EventParameter_DTC_0x0d0400_CAN_Network_ETAS_BusOff_Event.GetEventExtendedDataRecordEx
            SynchronousServerCallPoint_28: operation=EvtInfo_EventParameter_DTC_0xc07388_Event.GetEventExtendedDataRecordEx
            SynchronousServerCallPoint_29: operation=EvtInfo_EventParameter_DTC_0xc12687_Event.GetEventExtendedDataRecordEx
            SynchronousServerCallPoint_30: operation=EvtInfo_EventParameter_DTC_0xc14587_Event.GetEventExtendedDataRecordEx
            SynchronousServerCallPoint_31: operation=EvtInfo_EventParameter_DTC_0xc22a87_Event.GetEventExtendedDataRecordEx
            SynchronousServerCallPoint_32: operation=EvtInfo_EventParameter_DTC_0xc41487_Event.GetEventExtendedDataRecordEx
            SynchronousServerCallPoint_33: operation=EvtInfo_EventParameter_DTC_0xd56217_Event.GetEventExtendedDataRecordEx
            SynchronousServerCallPoint_34: operation=EvtInfo_EventParameter_DTC_0xd56316_Event.GetEventExtendedDataRecordEx
            SynchronousServerCallPoint_35: operation=EvtInfo_EventParameter_DTC_0xe00141_Event.GetEventExtendedDataRecordEx
            SynchronousServerCallPoint_36: operation=EvtInfo_EventParameter_DTC_0xe00142_Event.GetEventExtendedDataRecordEx
            SynchronousServerCallPoint_37: operation=EvtInfo_EventParameter_DTC_0xe26200_Event.GetEventExtendedDataRecordEx
        GetEventExtendedDataRecord_Adapt_Appl
          12 x sync call:
            SynchronousServerCallPoint_26: operation=EvtInfo_EventParameter_DTC_0x000001_Event.GetEventExtendedDataRecord
            SynchronousServerCallPoint_27: operation=EvtInfo_EventParameter_DTC_0x0d0400_CAN_Network_ETAS_BusOff_Event.GetEventExtendedDataRecord
            SynchronousServerCallPoint_28: operation=EvtInfo_EventParameter_DTC_0xc07388_Event.GetEventExtendedDataRecord
            SynchronousServerCallPoint_29: operation=EvtInfo_EventParameter_DTC_0xc12687_Event.GetEventExtendedDataRecord
            SynchronousServerCallPoint_30: operation=EvtInfo_EventParameter_DTC_0xc14587_Event.GetEventExtendedDataRecord
            SynchronousServerCallPoint_31: operation=EvtInfo_EventParameter_DTC_0xc22a87_Event.GetEventExtendedDataRecord
            SynchronousServerCallPoint_32: operation=EvtInfo_EventParameter_DTC_0xc41487_Event.GetEventExtendedDataRecord
            SynchronousServerCallPoint_33: operation=EvtInfo_EventParameter_DTC_0xd56217_Event.GetEventExtendedDataRecord
            SynchronousServerCallPoint_34: operation=EvtInfo_EventParameter_DTC_0xd56316_Event.GetEventExtendedDataRecord
            SynchronousServerCallPoint_35: operation=EvtInfo_EventParameter_DTC_0xe00141_Event.GetEventExtendedDataRecord
            SynchronousServerCallPoint_36: operation=EvtInfo_EventParameter_DTC_0xe00142_Event.GetEventExtendedDataRecord
            SynchronousServerCallPoint_37: operation=EvtInfo_EventParameter_DTC_0xe26200_Event.GetEventExtendedDataRecord
        GetEventFailed_Adapt_Appl
          12 x sync call:
            SynchronousServerCallPoint_26: operation=EvtInfo_EventParameter_DTC_0x000001_Event.GetEventFailed
            SynchronousServerCallPoint_27: operation=EvtInfo_EventParameter_DTC_0x0d0400_CAN_Network_ETAS_BusOff_Event.GetEventFailed
            SynchronousServerCallPoint_28: operation=EvtInfo_EventParameter_DTC_0xc07388_Event.GetEventFailed
            SynchronousServerCallPoint_29: operation=EvtInfo_EventParameter_DTC_0xc12687_Event.GetEventFailed
            SynchronousServerCallPoint_30: operation=EvtInfo_EventParameter_DTC_0xc14587_Event.GetEventFailed
            SynchronousServerCallPoint_31: operation=EvtInfo_EventParameter_DTC_0xc22a87_Event.GetEventFailed
            SynchronousServerCallPoint_32: operation=EvtInfo_EventParameter_DTC_0xc41487_Event.GetEventFailed
            SynchronousServerCallPoint_33: operation=EvtInfo_EventParameter_DTC_0xd56217_Event.GetEventFailed
            SynchronousServerCallPoint_34: operation=EvtInfo_EventParameter_DTC_0xd56316_Event.GetEventFailed
            SynchronousServerCallPoint_35: operation=EvtInfo_EventParameter_DTC_0xe00141_Event.GetEventFailed
            SynchronousServerCallPoint_36: operation=EvtInfo_EventParameter_DTC_0xe00142_Event.GetEventFailed
            SynchronousServerCallPoint_37: operation=EvtInfo_EventParameter_DTC_0xe26200_Event.GetEventFailed
        GetEventFreezeFrameDataEx_Adapt_Appl
          12 x sync call:
            SynchronousServerCallPoint_26: operation=EvtInfo_EventParameter_DTC_0x000001_Event.GetEventFreezeFrameDataEx
            SynchronousServerCallPoint_27: operation=EvtInfo_EventParameter_DTC_0x0d0400_CAN_Network_ETAS_BusOff_Event.GetEventFreezeFrameDataEx
            SynchronousServerCallPoint_28: operation=EvtInfo_EventParameter_DTC_0xc07388_Event.GetEventFreezeFrameDataEx
            SynchronousServerCallPoint_29: operation=EvtInfo_EventParameter_DTC_0xc12687_Event.GetEventFreezeFrameDataEx
            SynchronousServerCallPoint_30: operation=EvtInfo_EventParameter_DTC_0xc14587_Event.GetEventFreezeFrameDataEx
            SynchronousServerCallPoint_31: operation=EvtInfo_EventParameter_DTC_0xc22a87_Event.GetEventFreezeFrameDataEx
            SynchronousServerCallPoint_32: operation=EvtInfo_EventParameter_DTC_0xc41487_Event.GetEventFreezeFrameDataEx
            SynchronousServerCallPoint_33: operation=EvtInfo_EventParameter_DTC_0xd56217_Event.GetEventFreezeFrameDataEx
            SynchronousServerCallPoint_34: operation=EvtInfo_EventParameter_DTC_0xd56316_Event.GetEventFreezeFrameDataEx
            SynchronousServerCallPoint_35: operation=EvtInfo_EventParameter_DTC_0xe00141_Event.GetEventFreezeFrameDataEx
            SynchronousServerCallPoint_36: operation=EvtInfo_EventParameter_DTC_0xe00142_Event.GetEventFreezeFrameDataEx
            SynchronousServerCallPoint_37: operation=EvtInfo_EventParameter_DTC_0xe26200_Event.GetEventFreezeFrameDataEx
        GetEventFreezeFrameData_Adapt_Appl
          12 x sync call:
            SynchronousServerCallPoint_26: operation=EvtInfo_EventParameter_DTC_0x000001_Event.GetEventFreezeFrameData
            SynchronousServerCallPoint_27: operation=EvtInfo_EventParameter_DTC_0x0d0400_CAN_Network_ETAS_BusOff_Event.GetEventFreezeFrameData
            SynchronousServerCallPoint_28: operation=EvtInfo_EventParameter_DTC_0xc07388_Event.GetEventFreezeFrameData
            SynchronousServerCallPoint_29: operation=EvtInfo_EventParameter_DTC_0xc12687_Event.GetEventFreezeFrameData
            SynchronousServerCallPoint_30: operation=EvtInfo_EventParameter_DTC_0xc14587_Event.GetEventFreezeFrameData
            SynchronousServerCallPoint_31: operation=EvtInfo_EventParameter_DTC_0xc22a87_Event.GetEventFreezeFrameData
            SynchronousServerCallPoint_32: operation=EvtInfo_EventParameter_DTC_0xc41487_Event.GetEventFreezeFrameData
            SynchronousServerCallPoint_33: operation=EvtInfo_EventParameter_DTC_0xd56217_Event.GetEventFreezeFrameData
            SynchronousServerCallPoint_34: operation=EvtInfo_EventParameter_DTC_0xd56316_Event.GetEventFreezeFrameData
            SynchronousServerCallPoint_35: operation=EvtInfo_EventParameter_DTC_0xe00141_Event.GetEventFreezeFrameData
            SynchronousServerCallPoint_36: operation=EvtInfo_EventParameter_DTC_0xe00142_Event.GetEventFreezeFrameData
            SynchronousServerCallPoint_37: operation=EvtInfo_EventParameter_DTC_0xe26200_Event.GetEventFreezeFrameData
        GetEventStatus_Adapt_Appl
          12 x sync call:
            SynchronousServerCallPoint_26: operation=EvtInfo_EventParameter_DTC_0x000001_Event.GetEventStatus
            SynchronousServerCallPoint_27: operation=EvtInfo_EventParameter_DTC_0x0d0400_CAN_Network_ETAS_BusOff_Event.GetEventStatus
            SynchronousServerCallPoint_28: operation=EvtInfo_EventParameter_DTC_0xc07388_Event.GetEventStatus
            SynchronousServerCallPoint_29: operation=EvtInfo_EventParameter_DTC_0xc12687_Event.GetEventStatus
            SynchronousServerCallPoint_30: operation=EvtInfo_EventParameter_DTC_0xc14587_Event.GetEventStatus
            SynchronousServerCallPoint_31: operation=EvtInfo_EventParameter_DTC_0xc22a87_Event.GetEventStatus
            SynchronousServerCallPoint_32: operation=EvtInfo_EventParameter_DTC_0xc41487_Event.GetEventStatus
            SynchronousServerCallPoint_33: operation=EvtInfo_EventParameter_DTC_0xd56217_Event.GetEventStatus
            SynchronousServerCallPoint_34: operation=EvtInfo_EventParameter_DTC_0xd56316_Event.GetEventStatus
            SynchronousServerCallPoint_35: operation=EvtInfo_EventParameter_DTC_0xe00141_Event.GetEventStatus
            SynchronousServerCallPoint_36: operation=EvtInfo_EventParameter_DTC_0xe00142_Event.GetEventStatus
            SynchronousServerCallPoint_37: operation=EvtInfo_EventParameter_DTC_0xe26200_Event.GetEventStatus
        GetEventTested_Adapt_Appl
          12 x sync call:
            SynchronousServerCallPoint_26: operation=EvtInfo_EventParameter_DTC_0x000001_Event.GetEventTested
            SynchronousServerCallPoint_27: operation=EvtInfo_EventParameter_DTC_0x0d0400_CAN_Network_ETAS_BusOff_Event.GetEventTested
            SynchronousServerCallPoint_28: operation=EvtInfo_EventParameter_DTC_0xc07388_Event.GetEventTested
            SynchronousServerCallPoint_29: operation=EvtInfo_EventParameter_DTC_0xc12687_Event.GetEventTested
            SynchronousServerCallPoint_30: operation=EvtInfo_EventParameter_DTC_0xc14587_Event.GetEventTested
            SynchronousServerCallPoint_31: operation=EvtInfo_EventParameter_DTC_0xc22a87_Event.GetEventTested
            SynchronousServerCallPoint_32: operation=EvtInfo_EventParameter_DTC_0xc41487_Event.GetEventTested
            SynchronousServerCallPoint_33: operation=EvtInfo_EventParameter_DTC_0xd56217_Event.GetEventTested
            SynchronousServerCallPoint_34: operation=EvtInfo_EventParameter_DTC_0xd56316_Event.GetEventTested
            SynchronousServerCallPoint_35: operation=EvtInfo_EventParameter_DTC_0xe00141_Event.GetEventTested
            SynchronousServerCallPoint_36: operation=EvtInfo_EventParameter_DTC_0xe00142_Event.GetEventTested
            SynchronousServerCallPoint_37: operation=EvtInfo_EventParameter_DTC_0xe26200_Event.GetEventTested
        GetFaultDetectionCounter_Adapt_Appl
          12 x sync call:
            SynchronousServerCallPoint_26: operation=EvtInfo_EventParameter_DTC_0x000001_Event.GetFaultDetectionCounter
            SynchronousServerCallPoint_27: operation=EvtInfo_EventParameter_DTC_0x0d0400_CAN_Network_ETAS_BusOff_Event.GetFaultDetectionCounter
            SynchronousServerCallPoint_28: operation=EvtInfo_EventParameter_DTC_0xc07388_Event.GetFaultDetectionCounter
            SynchronousServerCallPoint_29: operation=EvtInfo_EventParameter_DTC_0xc12687_Event.GetFaultDetectionCounter
            SynchronousServerCallPoint_30: operation=EvtInfo_EventParameter_DTC_0xc14587_Event.GetFaultDetectionCounter
            SynchronousServerCallPoint_31: operation=EvtInfo_EventParameter_DTC_0xc22a87_Event.GetFaultDetectionCounter
            SynchronousServerCallPoint_32: operation=EvtInfo_EventParameter_DTC_0xc41487_Event.GetFaultDetectionCounter
            SynchronousServerCallPoint_33: operation=EvtInfo_EventParameter_DTC_0xd56217_Event.GetFaultDetectionCounter
            SynchronousServerCallPoint_34: operation=EvtInfo_EventParameter_DTC_0xd56316_Event.GetFaultDetectionCounter
            SynchronousServerCallPoint_35: operation=EvtInfo_EventParameter_DTC_0xe00141_Event.GetFaultDetectionCounter
            SynchronousServerCallPoint_36: operation=EvtInfo_EventParameter_DTC_0xe00142_Event.GetFaultDetectionCounter
            SynchronousServerCallPoint_37: operation=EvtInfo_EventParameter_DTC_0xe26200_Event.GetFaultDetectionCounter
        GetOperationCycleState_Adapt_Appl
          sync call SynchronousServerCallPoint_0: operation=OpCycle_DemOpCycle_DEM_POWER.GetOperationCycleState
        GetStorageCondition_Adapt_Appl
          sync call SynchronousServerCallPoint_0: operation=StorageCond_DemStorageCondition_0.GetStorageCondition
        PrestoreFreezeFrame_Adapt_Appl
          11 x sync call:
            SynchronousServerCallPoint_0: operation=Event_EventParameter_DTC_0x000001_Event.PrestoreFreezeFrame
            SynchronousServerCallPoint_1: operation=Event_EventParameter_DTC_0xc07388_Event.PrestoreFreezeFrame
            SynchronousServerCallPoint_10: operation=Event_EventParameter_DTC_0xe26200_Event.PrestoreFreezeFrame
            SynchronousServerCallPoint_2: operation=Event_EventParameter_DTC_0xc12687_Event.PrestoreFreezeFrame
            SynchronousServerCallPoint_3: operation=Event_EventParameter_DTC_0xc14587_Event.PrestoreFreezeFrame
            SynchronousServerCallPoint_4: operation=Event_EventParameter_DTC_0xc22a87_Event.PrestoreFreezeFrame
            SynchronousServerCallPoint_5: operation=Event_EventParameter_DTC_0xc41487_Event.PrestoreFreezeFrame
            SynchronousServerCallPoint_6: operation=Event_EventParameter_DTC_0xd56217_Event.PrestoreFreezeFrame
            SynchronousServerCallPoint_7: operation=Event_EventParameter_DTC_0xd56316_Event.PrestoreFreezeFrame
            SynchronousServerCallPoint_8: operation=Event_EventParameter_DTC_0xe00141_Event.PrestoreFreezeFrame
            SynchronousServerCallPoint_9: operation=Event_EventParameter_DTC_0xe00142_Event.PrestoreFreezeFrame
        ResetEventDebounceStatus_Adapt_Appl
          11 x sync call:
            SynchronousServerCallPoint_0: operation=Event_EventParameter_DTC_0x000001_Event.ResetEventDebounceStatus
            SynchronousServerCallPoint_1: operation=Event_EventParameter_DTC_0xc07388_Event.ResetEventDebounceStatus
            SynchronousServerCallPoint_10: operation=Event_EventParameter_DTC_0xe26200_Event.ResetEventDebounceStatus
            SynchronousServerCallPoint_2: operation=Event_EventParameter_DTC_0xc12687_Event.ResetEventDebounceStatus
            SynchronousServerCallPoint_3: operation=Event_EventParameter_DTC_0xc14587_Event.ResetEventDebounceStatus
            SynchronousServerCallPoint_4: operation=Event_EventParameter_DTC_0xc22a87_Event.ResetEventDebounceStatus
            SynchronousServerCallPoint_5: operation=Event_EventParameter_DTC_0xc41487_Event.ResetEventDebounceStatus
            SynchronousServerCallPoint_6: operation=Event_EventParameter_DTC_0xd56217_Event.ResetEventDebounceStatus
            SynchronousServerCallPoint_7: operation=Event_EventParameter_DTC_0xd56316_Event.ResetEventDebounceStatus
            SynchronousServerCallPoint_8: operation=Event_EventParameter_DTC_0xe00141_Event.ResetEventDebounceStatus
            SynchronousServerCallPoint_9: operation=Event_EventParameter_DTC_0xe00142_Event.ResetEventDebounceStatus
        ResetEventStatus_Adapt_Appl
          11 x sync call:
            SynchronousServerCallPoint_0: operation=Event_EventParameter_DTC_0x000001_Event.ResetEventStatus
            SynchronousServerCallPoint_1: operation=Event_EventParameter_DTC_0xc07388_Event.ResetEventStatus
            SynchronousServerCallPoint_10: operation=Event_EventParameter_DTC_0xe26200_Event.ResetEventStatus
            SynchronousServerCallPoint_2: operation=Event_EventParameter_DTC_0xc12687_Event.ResetEventStatus
            SynchronousServerCallPoint_3: operation=Event_EventParameter_DTC_0xc14587_Event.ResetEventStatus
            SynchronousServerCallPoint_4: operation=Event_EventParameter_DTC_0xc22a87_Event.ResetEventStatus
            SynchronousServerCallPoint_5: operation=Event_EventParameter_DTC_0xc41487_Event.ResetEventStatus
            SynchronousServerCallPoint_6: operation=Event_EventParameter_DTC_0xd56217_Event.ResetEventStatus
            SynchronousServerCallPoint_7: operation=Event_EventParameter_DTC_0xd56316_Event.ResetEventStatus
            SynchronousServerCallPoint_8: operation=Event_EventParameter_DTC_0xe00141_Event.ResetEventStatus
            SynchronousServerCallPoint_9: operation=Event_EventParameter_DTC_0xe00142_Event.ResetEventStatus
        RoutineServices_DcmDspRoutine_Routine_Control_203_Start: can-be-invoked-concurrently=true
        RoutineServices_DcmDspRoutine_Routine_Control_ABFF_RequestResults: can-be-invoked-concurrently=true
        RoutineServices_DcmDspRoutine_Routine_Control_ABFF_Start: can-be-invoked-concurrently=true
        RoutineServices_DcmDspRoutine_X_Routine_Control_ABFE_Start: can-be-invoked-concurrently=true
        SecurityAccess_Unlocked_L1_CompareKey: can-be-invoked-concurrently=true
        SecurityAccess_Unlocked_L1_GetSeed: can-be-invoked-concurrently=true
        SecurityAccess_Unlocked_L3_CompareKey: can-be-invoked-concurrently=true
        SecurityAccess_Unlocked_L3_GetSeed: can-be-invoked-concurrently=true
        SetCycleQualified_Adapt_Appl
          sync call SynchronousServerCallPoint_0: operation=OpCycle_DemOpCycle_DEM_POWER.SetCycleQualified
        SetEventAvailable_Adapt_Appl
          11 x sync call:
            SynchronousServerCallPoint_0: operation=ControlEventAvailable_EventParameter_DTC_0x000001_Event.SetEventAvailable
            SynchronousServerCallPoint_1: operation=ControlEventAvailable_EventParameter_DTC_0xc07388_Event.SetEventAvailable
            SynchronousServerCallPoint_10: operation=ControlEventAvailable_EventParameter_DTC_0xe26200_Event.SetEventAvailable
            SynchronousServerCallPoint_2: operation=ControlEventAvailable_EventParameter_DTC_0xc12687_Event.SetEventAvailable
            SynchronousServerCallPoint_3: operation=ControlEventAvailable_EventParameter_DTC_0xc14587_Event.SetEventAvailable
            SynchronousServerCallPoint_4: operation=ControlEventAvailable_EventParameter_DTC_0xc22a87_Event.SetEventAvailable
            SynchronousServerCallPoint_5: operation=ControlEventAvailable_EventParameter_DTC_0xc41487_Event.SetEventAvailable
            SynchronousServerCallPoint_6: operation=ControlEventAvailable_EventParameter_DTC_0xd56217_Event.SetEventAvailable
            SynchronousServerCallPoint_7: operation=ControlEventAvailable_EventParameter_DTC_0xd56316_Event.SetEventAvailable
            SynchronousServerCallPoint_8: operation=ControlEventAvailable_EventParameter_DTC_0xe00141_Event.SetEventAvailable
            SynchronousServerCallPoint_9: operation=ControlEventAvailable_EventParameter_DTC_0xe00142_Event.SetEventAvailable
        SetEventStatusWithEnvdata_Adapt_Appl
          11 x sync call:
            SynchronousServerCallPoint_0: operation=Event_EventParameter_DTC_0x000001_Event.SetEventStatusWithEnvdata
            SynchronousServerCallPoint_1: operation=Event_EventParameter_DTC_0xc07388_Event.SetEventStatusWithEnvdata
            SynchronousServerCallPoint_10: operation=Event_EventParameter_DTC_0xe26200_Event.SetEventStatusWithEnvdata
            SynchronousServerCallPoint_2: operation=Event_EventParameter_DTC_0xc12687_Event.SetEventStatusWithEnvdata
            SynchronousServerCallPoint_3: operation=Event_EventParameter_DTC_0xc14587_Event.SetEventStatusWithEnvdata
            SynchronousServerCallPoint_4: operation=Event_EventParameter_DTC_0xc22a87_Event.SetEventStatusWithEnvdata
            SynchronousServerCallPoint_5: operation=Event_EventParameter_DTC_0xc41487_Event.SetEventStatusWithEnvdata
            SynchronousServerCallPoint_6: operation=Event_EventParameter_DTC_0xd56217_Event.SetEventStatusWithEnvdata
            SynchronousServerCallPoint_7: operation=Event_EventParameter_DTC_0xd56316_Event.SetEventStatusWithEnvdata
            SynchronousServerCallPoint_8: operation=Event_EventParameter_DTC_0xe00141_Event.SetEventStatusWithEnvdata
            SynchronousServerCallPoint_9: operation=Event_EventParameter_DTC_0xe00142_Event.SetEventStatusWithEnvdata
        SetEventStatus_Adapt_Appl
          11 x sync call:
            SynchronousServerCallPoint_0: operation=Event_EventParameter_DTC_0x000001_Event.SetEventStatus
            SynchronousServerCallPoint_1: operation=Event_EventParameter_DTC_0xc07388_Event.SetEventStatus
            SynchronousServerCallPoint_10: operation=Event_EventParameter_DTC_0xe26200_Event.SetEventStatus
            SynchronousServerCallPoint_2: operation=Event_EventParameter_DTC_0xc12687_Event.SetEventStatus
            SynchronousServerCallPoint_3: operation=Event_EventParameter_DTC_0xc14587_Event.SetEventStatus
            SynchronousServerCallPoint_4: operation=Event_EventParameter_DTC_0xc22a87_Event.SetEventStatus
            SynchronousServerCallPoint_5: operation=Event_EventParameter_DTC_0xc41487_Event.SetEventStatus
            SynchronousServerCallPoint_6: operation=Event_EventParameter_DTC_0xd56217_Event.SetEventStatus
            SynchronousServerCallPoint_7: operation=Event_EventParameter_DTC_0xd56316_Event.SetEventStatus
            SynchronousServerCallPoint_8: operation=Event_EventParameter_DTC_0xe00141_Event.SetEventStatus
            SynchronousServerCallPoint_9: operation=Event_EventParameter_DTC_0xe00142_Event.SetEventStatus
        SetOperationCycleState_Adapt_Appl
          sync call SynchronousServerCallPoint_0: operation=OpCycle_DemOpCycle_DEM_POWER.SetOperationCycleState
        SetStorageCondition_Adapt_Appl
          sync call SynchronousServerCallPoint_0: operation=StorageCond_DemStorageCondition_0.SetStorageCondition
        SetWIRStatus_Adapt_Appl
          11 x sync call:
            SynchronousServerCallPoint_0: operation=EventStatus_EventParameter_DTC_0x000001_Event.SetWIRStatus
            SynchronousServerCallPoint_1: operation=EventStatus_EventParameter_DTC_0xc07388_Event.SetWIRStatus
            SynchronousServerCallPoint_10: operation=EventStatus_EventParameter_DTC_0xe26200_Event.SetWIRStatus
            SynchronousServerCallPoint_2: operation=EventStatus_EventParameter_DTC_0xc12687_Event.SetWIRStatus
            SynchronousServerCallPoint_3: operation=EventStatus_EventParameter_DTC_0xc14587_Event.SetWIRStatus
            SynchronousServerCallPoint_4: operation=EventStatus_EventParameter_DTC_0xc22a87_Event.SetWIRStatus
            SynchronousServerCallPoint_5: operation=EventStatus_EventParameter_DTC_0xc41487_Event.SetWIRStatus
            SynchronousServerCallPoint_6: operation=EventStatus_EventParameter_DTC_0xd56217_Event.SetWIRStatus
            SynchronousServerCallPoint_7: operation=EventStatus_EventParameter_DTC_0xd56316_Event.SetWIRStatus
            SynchronousServerCallPoint_8: operation=EventStatus_EventParameter_DTC_0xe00141_Event.SetWIRStatus
            SynchronousServerCallPoint_9: operation=EventStatus_EventParameter_DTC_0xe00142_Event.SetWIRStatus
package /Composition/DiagUT/SwcImplementation
  swc implementation IMPL_DiagUT: programming-language=C, behavior=IB_DiagUT
    code-descriptors:
      code CodeDesc_DiagUT: artifact-descriptors=autosar-engineering-object=category=SWSRC
